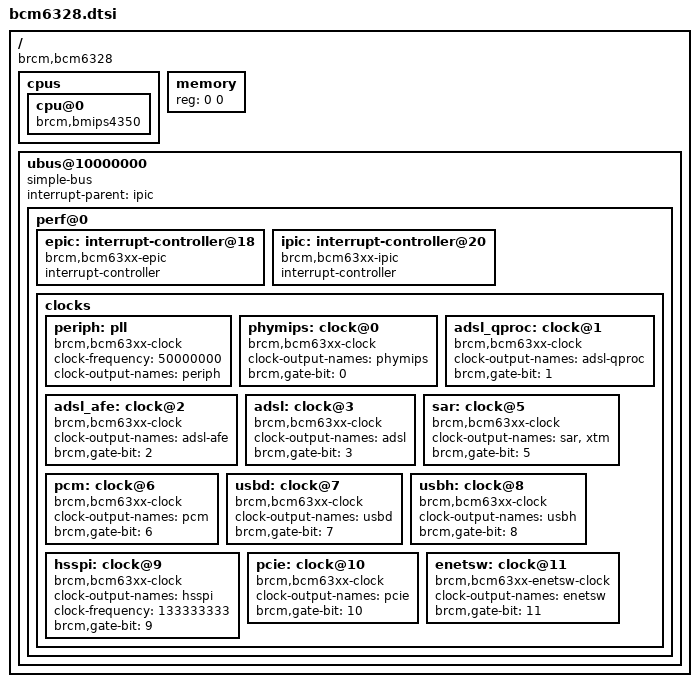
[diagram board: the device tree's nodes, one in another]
/*
 * Device Tree Include file for Broadcom BCM6328 SoC
 *
 * Copyright (C) 2012 Jonas Gorski <jonas.gorski@gmail.com>
 *
 * This file is licensed under the terms of the GNU General Public License
 * version 2.  This program is licensed "as is" without any warranty of any
 * kind, whether express or implied.
 */

/ {
	#address-cells = <1>;
	#size-cells = <1>;
	compatible = "brcm,bcm6328";

	cpus {
		cpu@0 {
			compatible = "brcm,bmips4350", "mips,mips4Kc";
		};
	};

	memory { device_type = "memory"; reg = <0 0>; };

	ubus@10000000 {
		#address-cells = <1>;
		#size-cells = <1>;
		ranges = <0 0x10000000 0x20000>;
		compatible = "simple-bus";

		interrupt-parent = <&ipic>;

		perf@0 {
			epic: interrupt-controller@18 {
				compatible = "brcm,bcm63xx-epic";
				interrupt-controller;
				#interrupt-cells = <2>;
			};

			ipic: interrupt-controller@20 {
				compatible = "brcm,bcm63xx-ipic";
				interrupt-controller;
				#interrupt-cells = <1>;
			};

			clocks {
				#address-cells = <1>;
				#size-cells = <0>;

				periph: pll {
					compatible = "brcm,bcm63xx-clock";
					#clock-cells = <0>;
					clock-frequency = <50000000>;
					clock-output-names = "periph";
				};

				phymips: clock@0 {
					compatible = "brcm,bcm63xx-clock";
					#clock-cells = <0>;
					clock-output-names = "phymips";
					brcm,gate-bit = <0>;
				};

				adsl_qproc: clock@1 {
					compatible = "brcm,bcm63xx-clock";
					#clock-cells = <0>;
					clock-output-names = "adsl-qproc";
					brcm,gate-bit = <1>;
				};

				adsl_afe: clock@2 {
					compatible = "brcm,bcm63xx-clock";
					#clock-cells = <0>;
					clock-output-names = "adsl-afe";
					brcm,gate-bit = <2>;
				};

				adsl: clock@3 {
					compatible = "brcm,bcm63xx-clock";
					#clock-cells = <0>;
					clock-output-names = "adsl";
					brcm,gate-bit = <3>;
				};

				sar: clock@5 {
					compatible = "brcm,bcm63xx-clock";
					#clock-cells = <0>;
					clock-output-names = "sar", "xtm";
					brcm,gate-bit = <5>;
				};

				pcm: clock@6 {
					compatible = "brcm,bcm63xx-clock";
					#clock-cells = <0>;
					clock-output-names = "pcm";
					brcm,gate-bit = <6>;
				};

				usbd: clock@7 {
					compatible = "brcm,bcm63xx-clock";
					#clock-cells = <0>;
					clock-output-names = "usbd";
					brcm,gate-bit = <7>;
				};

				usbh: clock@8 {
					compatible = "brcm,bcm63xx-clock";
					#clock-cells = <0>;
					clock-output-names = "usbh";
					brcm,gate-bit = <8>;
				};

				hsspi: clock@9 {
					compatible = "brcm,bcm63xx-clock";
					#clock-cells = <0>;
					clock-output-names = "hsspi";
					clock-frequency = <133333333>;
					brcm,gate-bit = <9>;
				};

				pcie: clock@10 {
					compatible = "brcm,bcm63xx-clock";
					#clock-cells = <0>;
					clock-output-names = "pcie";
					brcm,gate-bit = <10>;
				};

				enetsw: clock@11 {
					compatible = "brcm,bcm63xx-enetsw-clock";
					#clock-cells = <0>;
					clock-output-names = "enetsw";
					brcm,gate-bit = <11>;
				};
			};
		};
	};
};
